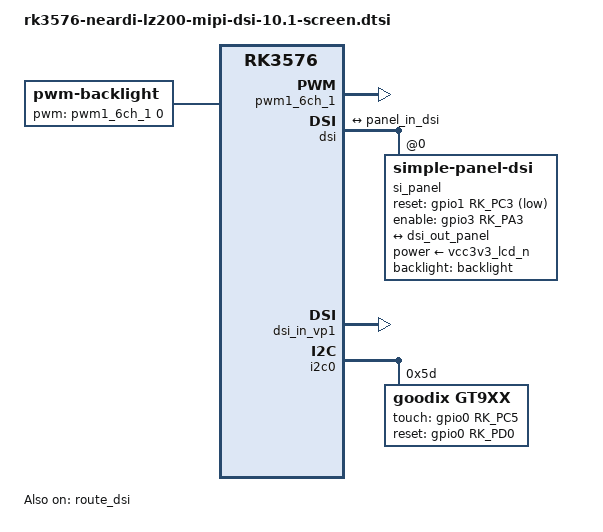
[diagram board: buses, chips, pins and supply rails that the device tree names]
&{/} {
    backlight: backlight {
		compatible = "pwm-backlight";
		pwms = <&pwm1_6ch_1 0 25000 1>;
		brightness-levels = <
			  0  20  20  21  21  22  22  23
			 23  24  24  25  25  26  26  27
			 27  28  28  29  29  30  30  31
			 31  32  32  33  33  34  34  35
			 35  36  36  37  37  38  38  39
			 40  41  42  43  44  45  46  47
			 48  49  50  51  52  53  54  55
			 56  57  58  59  60  61  62  63
			 64  65  66  67  68  69  70  71
			 72  73  74  75  76  77  78  79
			 80  81  82  83  84  85  86  87
			 88  89  90  91  92  93  94  95
			 96  97  98  99 100 101 102 103
			104 105 106 107 108 109 110 111
			112 113 114 115 116 117 118 119
			120 121 122 123 124 125 126 127
			128 129 130 131 132 133 134 135
			136 137 138 139 140 141 142 143
			144 145 146 147 148 149 150 151
			152 153 154 155 156 157 158 159
			160 161 162 163 164 165 166 167
			168 169 170 171 172 173 174 175
			176 177 178 179 180 181 182 183
			184 185 186 187 188 189 190 191
			192 193 194 195 196 197 198 199
			200 201 202 203 204 205 206 207
			208 209 210 211 212 213 214 215
			216 217 218 219 220 221 222 223
			224 225 226 227 228 229 230 231
			232 233 234 235 236 237 238 239
			240 241 242 243 244 245 246 247
			248 249 250 251 252 253 254 255
		>;
		default-brightness-level = <200>;
	};
};

&pwm1_6ch_1 {
	status = "okay";
	pinctrl-0 = <&pwm1m0_ch1>;
};

&dsi {
	status = "okay";
	//rockchip,lane-rate = <450>; 
    si_panel: panel@0 {
        status = "okay";
        compatible = "simple-panel-dsi";
        reg = <0>;
        backlight = <&backlight>;
        prepare-delay-ms = <5>;
        reset-delay-ms = <1>;
        init-delay-ms = <80>;
        disable-delay-ms = <10>;
        unprepare-delay-ms = <5>;
        width-mm = <83>;
        height-mm = <83>;

        reset-gpios = <&gpio1 RK_PC3 GPIO_ACTIVE_LOW>;
        enable-gpios = <&gpio3 RK_PA3 GPIO_ACTIVE_HIGH>;
        pinctrl-names = "default";
        pinctrl-0 = <&bl_pwr_en>, <&panel_reset>;
        power-supply = <&vcc3v3_lcd_n>;
            
        dsi,flags = <(MIPI_DSI_MODE_VIDEO | MIPI_DSI_MODE_VIDEO_BURST |
                    MIPI_DSI_MODE_LPM | MIPI_DSI_MODE_NO_EOT_PACKET)>;
        dsi,format = <MIPI_DSI_FMT_RGB888>;
        dsi,lanes  = <2>;
        panel-init-sequence = [            
            39 00 04 FF 98 81 03
            15 00 02 01 00
            15 00 02 02 00
            15 00 02 03 53
            15 00 02 04 D3
            15 00 02 05 00
            15 00 02 06 0D
            15 00 02 07 08
            15 00 02 08 00
            15 00 02 09 00
            15 00 02 0a 00
            15 00 02 0b 00
            15 00 02 0c 00
            15 00 02 0d 00
            15 00 02 0e 00
            15 00 02 0f 28
            15 00 02 10 28
            15 00 02 11 00           
            15 00 02 12 00        
            15 00 02 13 00
            15 00 02 14 00
            15 00 02 15 00
            15 00 02 16 00
            15 00 02 17 00
            15 00 02 18 00
            15 00 02 19 00
            15 00 02 1a 00
            15 00 02 1b 00   
            15 00 02 1c 00
            15 00 02 1d 00
            15 00 02 1e 40
            15 00 02 1f 80
            15 00 02 20 06
            15 00 02 21 01
            15 00 02 22 00
            15 00 02 23 00
            15 00 02 24 00
            15 00 02 25 00
            15 00 02 26 00
            15 00 02 27 00
            15 00 02 28 33
            15 00 02 29 33
            15 00 02 2a 00  
            15 00 02 2b 00
            15 00 02 2c 00
            15 00 02 2d 00
            15 00 02 2e 00      
            15 00 02 2f 00
            15 00 02 30 00
            15 00 02 31 00
            15 00 02 32 00
            15 00 02 33 00
            15 00 02 34 03
            15 00 02 35 00
            15 00 02 36 00
            15 00 02 37 00
            15 00 02 38 96
            15 00 02 39 00
            15 00 02 3a 00 
            15 00 02 3b 00
            15 00 02 3c 00
            15 00 02 3d 00
            15 00 02 3e 00
            15 00 02 3f 00
            15 00 02 40 00
            15 00 02 41 00
            15 00 02 42 00
            15 00 02 43 00
            15 00 02 44 00
            15 00 02 50 00
            15 00 02 51 23
            15 00 02 52 45
            15 00 02 53 67
            15 00 02 54 89
            15 00 02 55 ab
            15 00 02 56 01
            15 00 02 57 23
            15 00 02 58 45
            15 00 02 59 67
            15 00 02 5a 89
            15 00 02 5b ab
            15 00 02 5c cd
            15 00 02 5d ef
            15 00 02 5e 00
            15 00 02 5f 08
            15 00 02 60 08
            15 00 02 61 06
            15 00 02 62 06
            15 00 02 63 01
            15 00 02 64 01
            15 00 02 65 00
            15 00 02 66 00
            15 00 02 67 02
            15 00 02 68 15
            15 00 02 69 15
            15 00 02 6a 14
            15 00 02 6b 14
            15 00 02 6c 0D
            15 00 02 6d 0D
            15 00 02 6e 0C
            15 00 02 6f 0C
            15 00 02 70 0F
            15 00 02 71 0F
            15 00 02 72 0E
            15 00 02 73 0E
            15 00 02 74 02
            15 00 02 75 08
            15 00 02 76 08
            15 00 02 77 06
            15 00 02 78 06
            15 00 02 79 01
            15 00 02 7a 01
            15 00 02 7b 00
            15 00 02 7c 00
            15 00 02 7d 02
            15 00 02 7e 15
            15 00 02 7f 15
            15 00 02 80 14
            15 00 02 81 14
            15 00 02 82 0D
            15 00 02 83 0D
            15 00 02 84 0C
            15 00 02 85 0C
            15 00 02 86 0F
            15 00 02 87 0F
            15 00 02 88 0E
            15 00 02 89 0E
            15 00 02 8A 02
            39 00 04 FF 98 81 04
            15 00 02 6E 2B
            15 00 02 6F 37
            15 00 02 3A A4
            15 00 02 8D 1A
            15 00 02 87 BA
            15 00 02 B2 D1
            15 00 02 88 0B
            15 00 02 38 01      
            15 00 02 39 00
            15 00 02 B5 07
            15 00 02 31 75
            15 00 02 3B 98
            39 00 04 FF 98 81 01
            15 00 02 22 0A
            15 00 02 31 00
            15 00 02 53 4D
            15 00 02 55 4D
            15 00 02 50 85
            15 00 02 51 80
            15 00 02 60 10
            15 00 02 62 20
            15 00 02 A0 00
            15 00 02 A1 06
            15 00 02 A2 1B
            15 00 02 A3 14
            15 00 02 A4 18
            15 00 02 A5 2E
            15 00 02 A6 22
            15 00 02 A7 24
            15 00 02 A8 85
            15 00 02 A9 1E
            15 00 02 AA 2A
            15 00 02 AB 74
            15 00 02 AC 1B
            15 00 02 AD 19
            15 00 02 AE 4C
            15 00 02 AF 21
            15 00 02 B0 27
            15 00 02 B1 4B
            15 00 02 B2 58
            15 00 02 B3 23
            15 00 02 C0 00
            15 00 02 C1 1F
            15 00 02 C2 29
            15 00 02 C3 12
            15 00 02 C4 14
            15 00 02 C5 25
            15 00 02 C6 19
            15 00 02 C7 1B
            15 00 02 C8 84
            15 00 02 C9 1D
            15 00 02 CA 28
            15 00 02 CB 73
            15 00 02 CC 1A
            15 00 02 CD 18
            15 00 02 CE 4D
            15 00 02 CF 23
            15 00 02 D0 29
            15 00 02 D1 4C
            15 00 02 D2 5B
            15 00 02 D3 23
            39 00 04 FF 98 81 00
            15 00 02 35 00
            15 00 02 11 00  
            15 78 02 00 00
            15 00 02 29 00
            15 0A 02 00 00
        ];
        
        panel-exit-sequence = [
			05 05 01 28
            05 78 01 10
		];

        disp_timings0: display-timings {
            native-mode = <&dsi_timing0>;
            dsi_timing0: timing0 {
                clock-frequency = <66000000>;
                hactive = <800>;
                vactive = <1280>;
                hback-porch = <48>;
                hfront-porch = <52>;
                vback-porch = <15>;
                vfront-porch = <16>;
                hsync-len = <8>;
                vsync-len = <6>;
                hsync-active = <0>;
                vsync-active = <0>;
                de-active = <0>;
                pixelclk-active = <0>;
            };
        };

        ports {
            #address-cells = <1>;
            #size-cells = <0>;       
            port@0 {
                reg = <0>;
                panel_in_dsi: endpoint {
                    remote-endpoint = <&dsi_out_panel>;
                };
            };
        };
    };

    ports {
        #address-cells = <1>;
        #size-cells = <0>;        
        port@1 {
            reg = <1>;
            dsi_out_panel: endpoint {
                remote-endpoint = <&panel_in_dsi>;
            };
        };
    };
};

&route_dsi {
	status = "okay";
    connect = <&vp1_out_dsi>;
};

&dsi_in_vp0 {
	status = "disabled";
};

&dsi_in_vp1 {
	status = "okay";
};

&dsi_in_vp2 {
	status = "disabled";
};

&dsi_in_vopl {
	status = "disabled";
};

/* touch panel */
&i2c0 {
    status = "okay";
    pinctrl-names = "default";
	pinctrl-0 = <&i2c0m1_xfer>;

    gt9xx: gt9xx@5d {
		compatible = "goodix,gt9xx";
		reg = <0x5d>;
		pinctrl-names = "default";
		pinctrl-0 = <&tp_gpio>;
		touch-gpio = <&gpio0 RK_PC5 GPIO_ACTIVE_HIGH>;
		reset-gpio = <&gpio0 RK_PD0 GPIO_ACTIVE_HIGH>;
		touchscreen-size-x = <800>;
		touchscreen-size-y = <1280>;
		max-x = <800>;
		max-y = <1280>;
		tp-size = <9111>;
		//tp-supply = <&vcc_tp>;
		wakeup-source;
		touchscreen-key-map = <158>; //KEY_HOMEPAGE=172,KEY_BACK=158,KEY_MENU=139
		goodix,driver-send-cfg = <0>;
		goodix,cfg-group0 =[
			42 00 03 00 04 0A 45 03 22 1F 28 0F 64 3C 03 0F 00 00 00 00 11 00
			08 00 00 00 00 8B 29 0E 71 6F B2 04 00 00 00 39 02 10 00 21 00 00
			00 03 64 32 00 00 00 3C 78 94 D5 02 07 00 00 04 C8 40 00 B1 4A 00
			9E 55 00 8E 61 00 7F 70 00 7F 70 00 00 00 F0 90 3C FF FF 07 00 00
			00 00 00 00 00 00 00 00 00 00 00 00 00 00 00 00 00 00 00 00 00 00
			00 00 1C 1A 18 16 14 12 10 0E 0C 0A 08 06 04 02 FF FF FF FF FF FF
			FF FF FF FF FF FF FF FF FF FF 00 02 04 06 08 0A 0C 0F 10 12 13 16
			18 1C 1D 1E 1F 20 21 22 FF FF FF FF FF FF FF FF FF FF FF FF FF FF
			FF FF FF FF FF FF FF FF F6 01
		];
	};
};

&pinctrl {
    lcd {
        panel_reset: panel_reset {
            rockchip,pins = <1 RK_PC3 RK_FUNC_GPIO &pcfg_pull_none>;
        };

        bl_pwr_en: bl_pwr_en {
            rockchip,pins = <3 RK_PA3 RK_FUNC_GPIO &pcfg_pull_none>;
        };
    };

    tp {
		tp_gpio: tp-gpio {
			rockchip,pins =
				<0 RK_PC5 RK_FUNC_GPIO &pcfg_pull_up>,
				<0 RK_PD0 RK_FUNC_GPIO &pcfg_pull_up>;
		};
	};
};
